# TC37XPD register map
Vendor: Infineon; Series: ATVMC; File version: 100
CPU: other r0p0, little endian, MPU, FPU, vendor SysTick, 4 interrupt priority bits
Registers are 32-bit, read-write, reset 0x0 unless marked. A register's access mark holds for its fields unless they carry their own. Offsets are from the block's base; [hi:lo] are bit positions; lines under a group give offsets from that group; {n}, {i} and the like mark numbered series; 'fields as' and 'values as' point back to an identical list.

## GTM (part 11 of 13)
Base 0xF0100000
{0xE8000+0x800*i} ATOM[{i}] (i=0..5) group
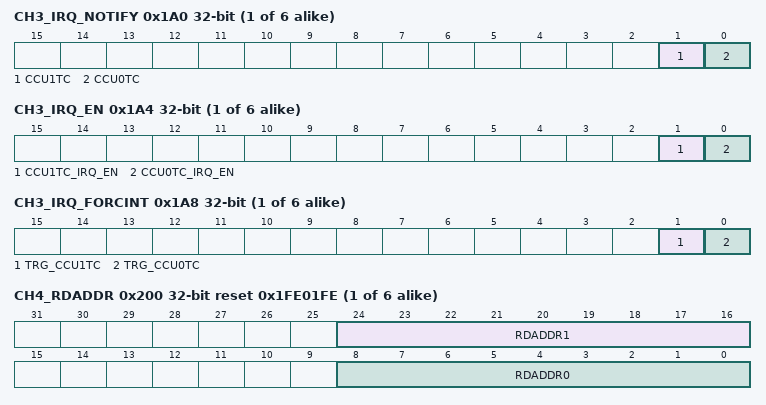
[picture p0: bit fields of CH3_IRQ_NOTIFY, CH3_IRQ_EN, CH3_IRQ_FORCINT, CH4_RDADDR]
  0x1A0 CH3_IRQ_NOTIFY — ATOM0 Channel 7 Interrupt Notification Register resetvalue={Application Reset:0x0}
    [1] CCU1TC — CCU1TC CCU1 Trigger condition interrupt for channel x. The notification of the interrupt is only triggered one time after reaching the condition CN0 gt CM1. To enable re trigger of the notification first the condition CN0 lt CM1 has to be reached. Note This bit will be cleared on a CPU write access of value 1. A read access leaves the bit unchanged. Note This description differs to the description in the Bosch spec. Note If bit SR0 TRIG is set to 1 only valid in SOMP mode this interrupt notify flag is set in case of SR0 is equal to CN0 and not set in case of CM1 gt lt CN0.
    [0] CCU0TC — CCU0 Trigger condition interrupt for channel x. The notification of the interrupt is only triggered one time after reaching the condition CN0 gt CM0. To enable re trigger of the notification first the condition CN0 lt CM1 has to be reached. Note This bit will be cleared on a CPU write access of value 1. A read access leaves the bit unchanged. Note This description differs to the description in the Bosch spec.
  0x1A4 CH3_IRQ_EN — ATOM0 Channel 7 Interrupt Enable Register resetvalue={Application Reset:0x0}
    [1] CCU1TC_IRQ_EN — ATOM CCU1TC IRQ interrupt enable. See bit 0.
    [0] CCU0TC_IRQ_EN — ATOM CCU0TC IRQ interrupt enable
  0x1A8 CH3_IRQ_FORCINT — ATOM0 Channel 7 Software Interrupt Generation Register resetvalue={Application Reset:0x0}
    [1] TRG_CCU1TC — Trigger ATOM CCU1TC IRQ interrupt by software. Note This bit is cleared automatically after write. Note This bit is write protected by bit RF PROT of register GTM CTRL
    [0] TRG_CCU0TC — Trigger ATOM CCU0TC IRQ interrupt by software. Note This bit is cleared automatically after write. Note This bit is write protected by bit RF PROT of register GTM CTRL
  0x1AC CH3_IRQ_MODE — ATOM0 Channel 7 Interrupt Mode Configuration Register resetvalue={Application Reset:0x0}
    [1:0] IRQ_MODE — IRQ mode selection. Note The interrupt modes are described in CROSSREFERENCE .
  0x200 CH4_RDADDR reset 0x1FE01FE — ATOM0 Channel 7 ARU read address Register resetvalue={Application Reset:0x1FE01FE}
    [24:16] RDADDR1 — ARU Read address 1. Note The ATOM channel switches to this read address when requested in the ARU control bits 52 to 48 with the pattern 111 . The channel switches back to the RDADDR0 after one ARU data package was received on RDADDR1 and the compare match event is occurred. Note This read address is only applicable in SOMC mode. Note This bit field is only writable if channel is disabled.
    [8:0] RDADDR0 — ARU Read address 0. Note This read address is used by the ATOM channel to receive data from ARU immediately after the channel and ARU access is enabled see ATOM i CH x CTRL register for details . Note This bit field is only writable if channel is disabled.
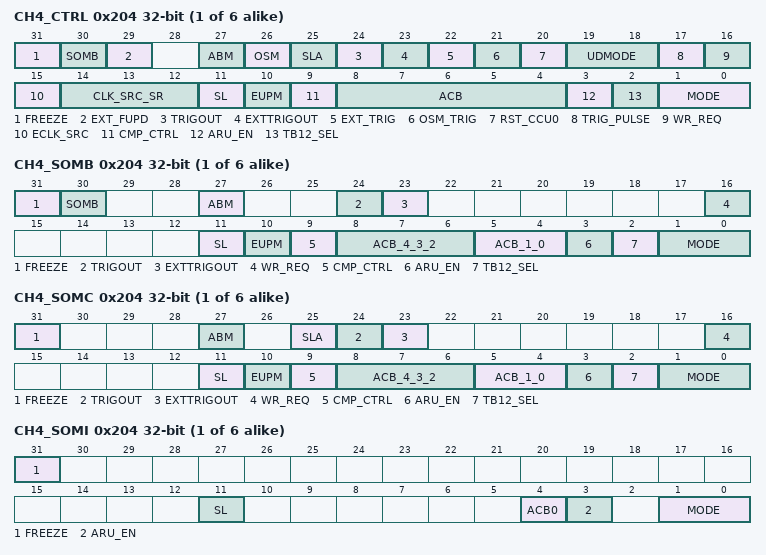
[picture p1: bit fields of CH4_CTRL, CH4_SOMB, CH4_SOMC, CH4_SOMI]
  0x204 CH4_CTRL (reset mask 0xFFFFF7FF) — ATOM0 Channel 7 Control Register resetvalue={Application Reset:0x0800,Application Reset:0x0,Application Reset:0x0,Application Reset:0x0,Application Reset:0x0,Application Reset:0x0}
    [31] FREEZE — FREEZE. Note if channel is disabled and ouptut is enabled in SOMP mode with UDMODE 0b00 the output is dependng directly on SL bit independent on FREEZE mode.
    [30] SOMB — SOMB mode
    [29] EXT_FUPD — External forced update. Note This bit is only applicable in SOMP and SOMS mode.
    [27] ABM — ARU blocking mode. Note This bit is only applicable in SOMC and SOMB mode.
    [26] OSM — One shot mode. Note This bit is only applicable in SOMP and SOMS modes.
    [25] SLA — Serve last ARU communication strategy. This bit is only applicable in SOMC mode. Please note that setting of this bit has only effect when ACBI 4 2 is configured for serve last compare strategy 100 101 or 110 . When this bit is not set the captured time stamps in the shadow registers SRx are only provided after the CCU1 match occurred. The ACBO 4 3 bits always return 10 in that case. By setting this bit the ATOM channel also provides the captured time stamps after the CCU0 match event to the ARU. The ACBO 4 3 bits are set to 01 in that case. After the CCU1 match event the time stamps are captured again in the SRx registers and provided to the ARU. The ACBO 4 3 bits are set to 10 . When the data in the shadow registers after the CCU0 match was not consumed by an ARU destination and the CCU1 match occurs the data in the shadow registers is overwritten by the new captured time stamps. The ATOM channel does not request new data from the ARU when the CCU0 match values are read from an ARU destination.
    [24] TRIGOUT — Trigger output selection output signal TRIG CHx of module ATOM CHx
    [23] EXTTRIGOUT — Select TIM EXT CAPTURE x as potential output signal TRIG x
    [22] EXT_TRIG — Select TIM EXT CAPTURE x as trigger signal
    [21] OSM_TRIG — Enable trigger of one shot pulse by trigger signal OSM TRIG. Note This bit should only be set if bit OSM 1 and bit RST CCU0 0.
    [20] RST_CCU0 — Reset source of CCU0. If RST CCU0 1 and UPEN CTRLx 1 are set TRIG x 1 or TIM EXT CAPTURE x triggers also the update of work register CM0 CM1 and CLK SRC . This bit is only applicable in SOMP mode. This bit should only be set if bit OSM 0 i.e. in continuous mode .
    [19:18] UDMODE — Up down counter mode. Note This mode is only applicable in SOMP mode.
    [17] TRIG_PULSE — Trigger output pulse length of one SYS CLK period
    [16] WR_REQ — CPU Write request bit for late compare register update. Note The CPU can disable subsequent ARU read requests by the channel and can update the shadow registers with new compare values while the compare units operate on old compare values received by former ARU accesses if occurred. Note On a compare match event the WR REQ bit will be reset by hardware. Note At the point of the force update only the shadow registers SR0 and SR1 are transferred into the CM0 CM1 registers. The output action is still defined by the ACBI bit field described by the ARU together with the old compare values for CM0 CM1. Note This bit is only applicable in SOMC and SOMB mode.
    [15] ECLK_SRC — Extend CLK SRC. Note This bit is only applicable in SOMP and SOMS mode. See bit CLK SRC SR description for details.
    [14:12] CLK_SRC_SR — Actual CMU clock source SOMS shadow register for CMU clock source SOMP . If ECLK SRC 0 ECLK SRC 1 This register is a shadow register for the register CLK SRC. Thus if the CMU CLK source for PWM generation should be changed during operation the old CMU CLK has to operate until the update of the ATOM channels internal CLK SRC register by the CLK SRC SR content is done either by an end of a period or a forced update. After channel reset the selected CLK SRC value is the SYS CLK input of Global Clock Divider . To use in SOMP mode one of the CMU CLKx it is recommended to perform a forced update of CLK SRC with the value of CLK SRC SR value before with enabling the channel. In case of ECLK SRC 1 and CLK SRC SR 011 100 101 110 a force update leads to an immediate update of CM0 CM1 and CLK SRC.
    [11] SL — Initial signal level. Reset value depends on the hardware configuration chosen by silicon vendor. If the output is disabled the output ATOM OUT x is set to inverse SL independent of the ATOM channel mode. If FREEZE 0 following notes are valid In SOMP SOMI SOMS mode if the channel is disabled the internal register SOUR inside ATOM sub unit SOU is set to inverse value of SL. By enabling the channel the register SOUR is not changed. Thus if the output is enabled afterwards the output ATOM OUT x is the inverse value of SL. In SOMC mode if the channel is disabled the internal register SOUR inside ATOM sub unit SOU is set to value of SL. By enabling the channel the register SOUR is not changed. Thus if the output is enabled and the channel is disabled the output ATOM OUT x is the value of SL. If FREEZE 1 the following notes are valid If the channel is disabled the output register of SOU unit is not changed and output ATOM OUT x is not changed.
    [10] EUPM — Extended update mode. If EUPM 1 a write access to CM0 or CM1 never causes an AEI write status 10 . This bit is only applicable in SOMC and SOMB mode.
    [9] CMP_CTRL — CCUx compare strategy select. Note This bit is only applicable in SOMC mode.
    [8:4] ACB — ATOM Mode control bits. These bits have different meaning in the different ATOM channel modes. Please refer to the mode description sections. SOMI CROSSREFERENCE and CROSSREFERENCE for register description. SOMC CROSSREFERENCE and CROSSREFERENCE for register description. SOMP CROSSREFERENCE and CROSSREFERENCE for register description. SOMS CROSSREFERENCE and CROSSREFERENCE for register description. SOMB CROSSREFERENCE and CROSSREFERENCE for register description.
    [3] ARU_EN — ARU input stream enable
    [2] TB12_SEL — Select time base value TBU TS1 or TBU TS2. Note This bit is only applicable in SOMC mode.
    [1:0] MODE — ATOM channel mode select
  0x204 CH4_SOMB (reset mask 0xFFFFF7FF) — ATOM0 Channel 7 Control Register in SOMB Mode resetvalue={Application Reset:0x0800,Application Reset:0x0,Application Reset:0x0,Application Reset:0x0,Application Reset:0x0,Application Reset:0x0}
    [31] FREEZE
    [30] SOMB — SOMB SOMB mode
    [27] ABM — ARU blocking mode
    [24] TRIGOUT — Trigger output selection output signal TRIG CHx of module ATOM CHx
    [23] EXTTRIGOUT — TIM EXT CAPTURE x as potential output signal TRIG x
    [16] WR_REQ — CPU Write request bit for late compare register update. The CPU can disable subsequent ARU read requests by the channel and can update the shadow registers with new compare values while the compare units operate on old compare values received by former ARU accesses if occurred. On a compare match event the WR REQ bit will be reset by hardware. At the point of the force update only the shadow registers SR0 and SR1 are transferred into the CM0 CM1 registers. The output action is still defined by the ACBI bit field described by the ARU together with the old compare values for CM0 CM1.
    [11] SL — Initial signal level after channel enable. Reset value depends on the hardware configuration chosen by silicon vendor. If the output is disabled the output ATOM OUT x is set to inverse value of SL. If FREEZE 0 the following note is valid If the channel is disabled the output register of SOU unit is set to value of SL. If FREEZE 1 the following note is valid If the channel is disabled the output register of SOU unit is not changed and output ATOM OUT x is not changed.
    [10] EUPM — Extended update mode. If EUPM 1 and after a CCU0 compare match if ARU EN 0 written CM0 value not stored. if ARU EN 1 ARU read request is continued and CM1 is updated until CCU1 compare match. Received CM0 is not stored. This bit is only applicable in SOMC and SOMB mode.
    [9] CMP_CTRL — CCUx compare strategy select. The compare unit CCU0 or CCU1 that compares against TBU TS0 depending on CCUx control mode defined by ACB CM 4 2 always performs a greater equal comparison independent of the CMP CTRL bit.
    [8:6] ACB_4_3_2 — ATOM SOMB compare strategy. These bits are only applicable if ARU EN 0.
    [5:4] ACB_1_0 — Signal level control bits. Note These bits are only applicable if ARU EN 0.
    [3] ARU_EN — ARU Input stream enable
    [2] TB12_SEL — Select time base value TBU TS1 or TBU TS2. This bit is only applicable if three time bases are present in the GTM. Otherwise this bit is reserved.
    [1:0] MODE — ATOM channel mode select. Not used in ATOM SOMB mode.
  0x204 CH4_SOMC (reset mask 0xFFFFF7FF) — ATOM0 Channel 7 Control Register in SOMC Mode resetvalue={Application Reset:0x0800,Application Reset:0x0,Application Reset:0x0,Application Reset:0x0,Application Reset:0x0,Application Reset:0x0}
    [31] FREEZE
    [27] ABM — ARU blocking mode
    [25] SLA — Serve last ARU communication strategy. Please note that setting of this bit has only effect when ACBI 4 2 is configured for serve last compare strategy quot 100 quot quot 101 quot or quot 110 quot . When this bit is not set the captured time stamps in the shadow registers SRx are only provided after the CCU1 match occurred. The ACBO 4 3 bits always return quot 10 quot in that case. By setting this bit the ATOM channel also provides the captured time stamps after the CCU0 match event to the ARU. The ACBO 4 3 bits are set to 8220 01 8221 in that case. After the CCU1 match event the time stamps are captured again in the SRx registers and provided to the ARU. The ACBO 4 3 bits are set to 8220 10 8221 . When the data in the shadow registers after the CCU0 match was not consumed by an ARU destination and the CCU1 match occurs the data in the shadow registers is overwritten by the new captured time stamps. The ATOM channel does not request new data from the ARU when the CCU0 match values are read from an ARU destination.
    [24] TRIGOUT — TRIGOUT Trigger output selection output signal TRIG CHx of module ATOM CHx
    [23] EXTTRIGOUT — Select TIM EXT CAPTURE x as potential output signal TRIG x
    [16] WR_REQ — CPU write request bit. The CPU can disable subsequent ARU read requests by the channel and can update the shadow registers with new compare values while the compare units operate on old compare values received by former ARU accesses if occurred. On a compare match event the WR REQ bit will be reset by hardware. At the point of the force update only the shadow registers SR0 and SR1 are transferred into the CM0 CM1 registers. The output action is still defined by the ACBI bit field described by the ARU together with the old compare values for CM0 CM1.
    [11] SL — Initial signal level after channel enable. Reset value depends on the hardware configuration chosen by silicon vendor. If the output is disabled the output ATOM OUT x is set to inverse value of SL. If FREEZE 0 following note is valid If the channel is disabled the output register of SOU unit is set to value of SL. If FREEZE 1 following note is valid If the channel is disabled the output register of SOU unit is not changed and output ATOM OUT x is not changed.
    [10] EUPM — Extended Update Mode. If EUPM 1 and after a CCU0 compare match If ARU EN 0 written CM0 value not stored. If ARU EN 1 ARU read request is continued and CM1 is updated until CCU1 compare match. Received CM0 values are not stored. This bit is only applicable in SOMC and SOMB mode.
    [9] CMP_CTRL — CCUx compare strategy select. The compare unit CCU0 or CCU1 that compares against TBU TS0 depending on CCUx control mode defined by ACBI 4 2 or ACB42 always performs a greater equal comparison independent on CMP CTRL bit.
    [8:6] ACB_4_3_2 — ATOM control bits ACB 4 ACB 3 ACB 2 . Independent of ARU EN a writing of 0b111 cancels any pending CCU0 or CCU1 compare. Note These bits are defining the compare strategy only if ARU EN 0.
    [5:4] ACB_1_0 — Signal level control bits. These bits are only applicable if ARU EN 0.
    [3] ARU_EN — ARU Input stream enable
    [2] TB12_SEL — Select time base value TBU TS1 or TBU TS2. This bit is only applicable if three time bases are present in the GTM. Otherwise this bit is reserved.
    [1:0] MODE — ATOM channel mode select
  0x204 CH4_SOMI (reset mask 0xFFFFF7FF) — ATOM0 Channel 7 Control Register in SOMI Mode resetvalue={Application Reset:0x0800,Application Reset:0x0,Application Reset:0x0,Application Reset:0x0,Application Reset:0x0,Application Reset:0x0}
    [31] FREEZE
    [11] SL — Initial signal level after channel is enabled. Note Reset value depends on the hardware configuration chosen by silicon vendor. Note If the output is disabled the output ATOM OUT x is set to inverse value of SL. If FREEZE 0 following note is valid If the channel is disabled the output register of SOU unit is set to inverse value of SL. If FREEZE 1 following note is valid If the channel is disabled the output register of SOU unit is not changed and output ATOM OUT x is not changed.
    [4] ACB0 — ACB bit 0 . Note Bosch name ACB 0 .
    [3] ARU_EN — ARU Input stream enable
    [1:0] MODE — ATOM channel mode select
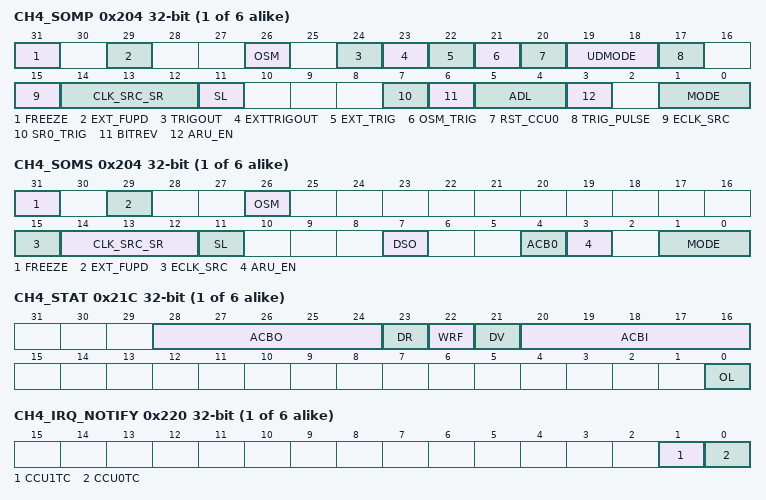
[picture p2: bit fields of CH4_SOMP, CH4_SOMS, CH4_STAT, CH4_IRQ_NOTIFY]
  0x204 CH4_SOMP (reset mask 0xFFFFF7FF) — ATOM0 Channel 7 Control Register in SOMP Mode resetvalue={Application Reset:0x0800,Application Reset:0x0,Application Reset:0x0,Application Reset:0x0,Application Reset:0x0,Application Reset:0x0}
    [31] FREEZE
    [29] EXT_FUPD — External forced update. This bit is only applicable in SOMP and SOMS mode.
    [26] OSM — One shot mode
    [24] TRIGOUT — Trigger output selection output signal TRIG CHx of module ATOM CHx
    [23] EXTTRIGOUT — Select TIM EXT CAPTURE x as potential output signal TRIG x
    [22] EXT_TRIG — Select TIM EXT CAPTURE x as trigger signal
    [21] OSM_TRIG — Enable trigger of one shot pulse by trigger signal OSM TRIG. This bit should only be set if bit OSM 1 and bit RST CCU0 0.
    [20] RST_CCU0 — Reset source of CCU0. If RST CCU0 1 and UPEN CTRLx 1 are set TRIG x 1 or TIM EXT CAPTURE x triggers also the update of work register CM0 CM1 and CLK SRC .
    [19:18] UDMODE — Up down counter mode. This mode is only applicable in SOMP mode.
    [17] TRIG_PULSE — Trigger output pulse length of one SYS CLK period
    [15] ECLK_SRC — Extend CLK SRC. See bit CLK SRC SR description for details.
    [14:12] CLK_SRC_SR — Shadow register for CMU clock source register CLK SRC. If ECLK SRC 0 ECLK SRC 1 This register is a shadow register for the register CLK SRC. Thus if the CMU CLK source for PWM generation should be changed during operation the old CMU CLK has to operate until the update of the ATOM channels internal CLK SRC register by the CLK SRC SR content is done either by an end of a period or a FORCE UPDATE. After channel reset the selected CLK SRC value is the SYS CLK input of Global Clock Divider . To use in SOMP mode one of the CMU CLKx it is recommended to perform a forced update of CLK SRC with the value of CLK SRC SR value before with enabling the channel.
    [11] SL — Signal level for pulse of PWM. Reset value depends on the hardware configuration chosen by silicon vendor. If the output is disabled the output ATOM OUT x is set to inverse value of SL FREEZE 0 the following note is valid If the channel is disabled the output register of SOU unit is set to inverse value of SL. If FREEZE 1 the following note is valid If the channel is disabled the output register of SOU unit is not changed and output ATOM OUT x is not changed.
    [7] SR0_TRIG — SR0 is used to generate a trigger on output ATOM i CH x OUT T if equal to CN0. This bit is only relevant in SOMP mode. This bit should only be set if RST CCU0 of this channel is 0.
    [6] BITREV — Bit reversing of output of counter register CN0. This bit enables the PCM mode. It is device specific in which channel the PCM mode is available. Please refer to device specific CROSSREFERENCE for this information.
    [5:4] ADL — ARU data select for SOMP. This bit field is only relevant in SOMP mode to select the ARU data source.
    [3] ARU_EN — ARU Input stream enable
    [1:0] MODE — ATOM channel mode select
  0x204 CH4_SOMS (reset mask 0xFFFFF7FF) — ATOM0 Channel 7 Control Register in SOMS Mode resetvalue={Application Reset:0x0800,Application Reset:0x0,Application Reset:0x0,Application Reset:0x0,Application Reset:0x0,Application Reset:0x0}
    [31] FREEZE
    [29] EXT_FUPD — External forced update. This bit is only applicable in SOMP and SOMS mode.
    [26] OSM — One shot mode
    [15] ECLK_SRC — Extend CLK SRC. See bit CLK SRC SR description for details.
    [14:12] CLK_SRC_SR — Shift frequency select for channel. If ECLK SRC 0 ECLK SRC 1 This register is a shadow register for the register CLK SRC. Thus if the CMU CLK source for PWM generation should be changed during operation the old CMU CLK has to operate until the update of the ATOM channels internal CLK SRC register by the CLK SRC SR content is done either by an end of a period or a FORCE UPDATE. After channel reset the selected CLK SRC value is the SYS CLK input of Global Clock Divider . To use in SOMP mode one of the CMU CLKx it is recommended to perform a forced update of CLK SRC with the value of CLK SRC SR value before with enabling the channel.
    [11] SL — Defines signal level when channel and output is disabling. Reset value depends on the hardware configuration chosen by silicon vendor. If the output is enabled the output ATOM OUT x is set to bit 0 or 23 of CM1 register. If the output is disabled the output ATOM OUT x is set to inverse value of SL. An enable or disable of the channel x has no effect on ATOM OUT x . The inverse value of SL is shifted into the CM1 register. If FREEZE 0 the following note is valid If the channel is disabled the output register of SOU unit is set to inverse value of SL. If FREEZE 1 the following note is valid If the channel is disabled the output register of SOU unit is not changed and output ATOM OUT x is not changed.
    [7] DSO — Double Shift Output. Note If DSO 1 only shift right is possible.
    [4] ACB0 — Shift direction for CM1 register. The data that has to be shifted out has to be aligned inside the CM1 register according to the defined shift direction. This bit is only applicable if ARU EN 0. If the direction ACB0 is changed the output ATOM OUT x switches immediately to the other first bit of CM1 bit 0 if ACB0 0 bit 23 if ACB0 160 160 1 .
    [3] ARU_EN — ARU Input stream enable
    [1:0] MODE — ATOM channel mode select
  0x208 CH4_SR0 — ATOM0 Channel 7 CCU0 Compare Shadow Register resetvalue={Application Reset:0x0}
    [23:0] SR0 — ATOM channel x shadow register SR0. Note The SR0 register is used as shadow register for CM0 in SOMP and SOMS modes and is used as capture register for time base TBU TS0 in SOMC mode.
  0x20C CH4_SR1 — ATOM0 Channel 7 CCU1 Compare Shadow Register resetvalue={Application Reset:0x0}
    [23:0] SR1 — ATOM channel x shadow register SR1. Note The SR1 register is used as shadow register for CM1 in SOMP and SOMS modes and is used as capture register for time base TBU TS1 or TBU TS2 when selected in ATOM i CH x CTRL register in SOMC mode.
  0x210 CH4_CM0 — ATOM0 Channel 7 CCU0 Compare Register resetvalue={Application Reset:0x0}
    [23:0] CM0 — ATOM CCU0 compare register
  0x214 CH4_CM1 — ATOM0 Channel 7 CCU1 Compare Register resetvalue={Application Reset:0x0}
    [23:0] CM1 — ATOM CCU1 compare register
  0x218 CH4_CN0 — ATOM0 Channel 7 CCU0 Counter Register resetvalue={Application Reset:0x0}
    [23:0] CN0 — ATOM CCU0 counter register
  0x21C CH4_STAT access per field — ATOM0 Channel 7 Status Register resetvalue={Application Reset:0x0}
    [28:24] ACBO ro — ATOM Internal status bits. ACBO 3 1 CCU0 Compare match occurred. ACBO 4 1 CCU1 Compare match occurred. Note These bits are only set in SOMC mode. Note ACBO is reset to 0b00000 on an update of register CM0 or CM1 via ARU or CPU . Note In SOMC mode these bits are sent as ARU control bits 52..48.
    [23] DR ro — ARU data rejected flag. Note The flag is cleared if valid data is received and stored via ARU.
    [22] WRF rw — Write request of CPU failed for late update. Note This bit is only applicable in SOMC and SOMB mode. Bit WRF can be reset by writing a 1 to it.
    [21] DV ro — Valid ARU Data stored in compare registers. Note This bit is only applicable in SOMC and SOMB mode. The CPU can determine the status of the ARU transfers with this bit. After the compare event occurred the bit is reset by hardware .
    [20:16] ACBI ro — ATOM Mode control bits. Note For ATOM SOMI SOMC SOMP and SOMS mode this register serves as a mirror for the five ARU control bits received through the ARU interface. The bits are valid when the DV bit is set. Note For SOMB mode this bit field serves as the work register of the compare strategy. It can be updated with the value of bit field ACB of register ATOM i CH x CTRL or the value of internal shadow register ACB SR.
    [0] OL ro — Actual output signal level of ATOM CHx OUT. Note Reset value is the inverted value of bit SL which depends on the hardware configuration chosen by silicon vendor.
  0x220 CH4_IRQ_NOTIFY — ATOM0 Channel 7 Interrupt Notification Register resetvalue={Application Reset:0x0}
    fields as ATOM[0].CH3_IRQ_NOTIFY
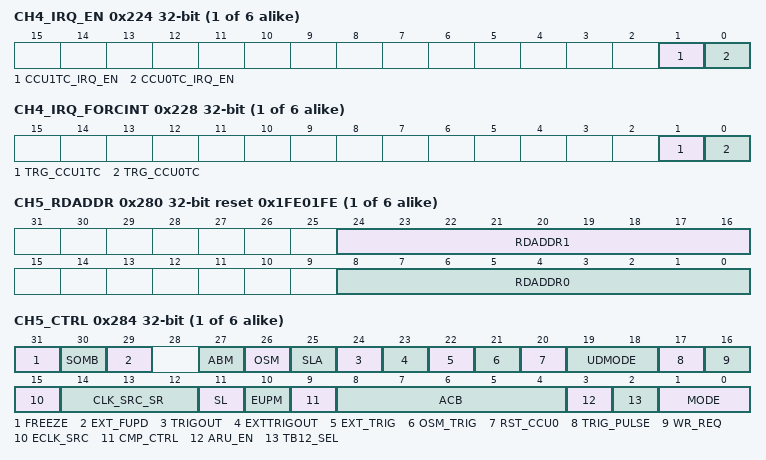
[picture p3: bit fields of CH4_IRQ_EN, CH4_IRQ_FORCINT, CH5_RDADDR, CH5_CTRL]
  0x224 CH4_IRQ_EN — ATOM0 Channel 7 Interrupt Enable Register resetvalue={Application Reset:0x0}
    fields as ATOM[0].CH3_IRQ_EN
  0x228 CH4_IRQ_FORCINT — ATOM0 Channel 7 Software Interrupt Generation Register resetvalue={Application Reset:0x0}
    fields as ATOM[0].CH3_IRQ_FORCINT
  0x22C CH4_IRQ_MODE — ATOM0 Channel 7 Interrupt Mode Configuration Register resetvalue={Application Reset:0x0}
    fields as ATOM[0].CH3_IRQ_MODE
  0x280 CH5_RDADDR reset 0x1FE01FE — ATOM0 Channel 7 ARU read address Register resetvalue={Application Reset:0x1FE01FE}
    fields as ATOM[0].CH4_RDADDR
  0x284 CH5_CTRL (reset mask 0xFFFFF7FF) — ATOM0 Channel 7 Control Register resetvalue={Application Reset:0x0800,Application Reset:0x0,Application Reset:0x0,Application Reset:0x0,Application Reset:0x0,Application Reset:0x0}
    fields as ATOM[0].CH4_CTRL
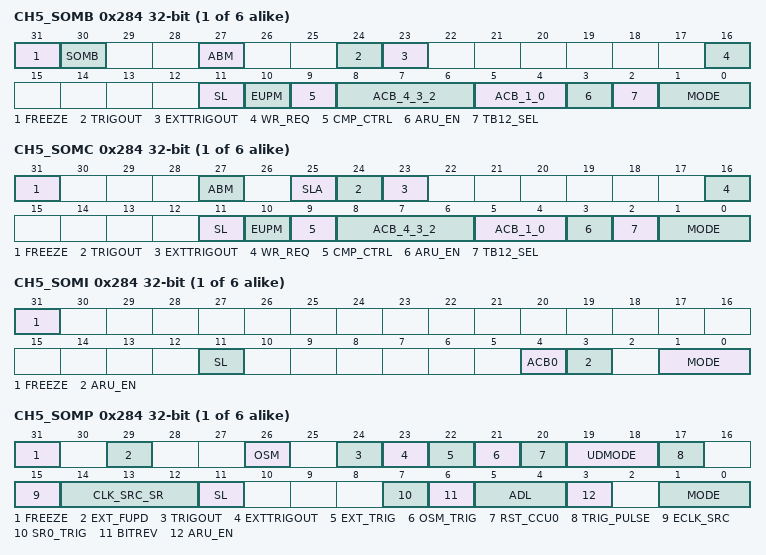
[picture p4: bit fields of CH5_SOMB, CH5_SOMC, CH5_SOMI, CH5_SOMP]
  0x284 CH5_SOMB (reset mask 0xFFFFF7FF) — ATOM0 Channel 7 Control Register in SOMB Mode resetvalue={Application Reset:0x0800,Application Reset:0x0,Application Reset:0x0,Application Reset:0x0,Application Reset:0x0,Application Reset:0x0}
    fields as ATOM[0].CH4_SOMB
  0x284 CH5_SOMC (reset mask 0xFFFFF7FF) — ATOM0 Channel 7 Control Register in SOMC Mode resetvalue={Application Reset:0x0800,Application Reset:0x0,Application Reset:0x0,Application Reset:0x0,Application Reset:0x0,Application Reset:0x0}
    fields as ATOM[0].CH4_SOMC
  0x284 CH5_SOMI (reset mask 0xFFFFF7FF) — ATOM0 Channel 7 Control Register in SOMI Mode resetvalue={Application Reset:0x0800,Application Reset:0x0,Application Reset:0x0,Application Reset:0x0,Application Reset:0x0,Application Reset:0x0}
    fields as ATOM[0].CH4_SOMI
  0x284 CH5_SOMP (reset mask 0xFFFFF7FF) — ATOM0 Channel 7 Control Register in SOMP Mode resetvalue={Application Reset:0x0800,Application Reset:0x0,Application Reset:0x0,Application Reset:0x0,Application Reset:0x0,Application Reset:0x0}
    fields as ATOM[0].CH4_SOMP
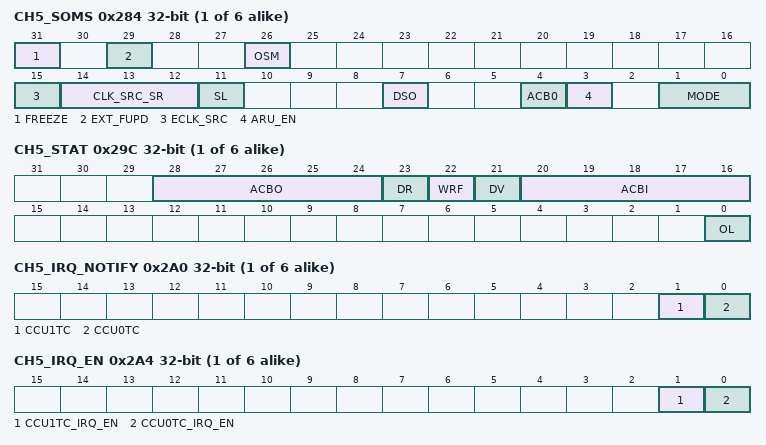
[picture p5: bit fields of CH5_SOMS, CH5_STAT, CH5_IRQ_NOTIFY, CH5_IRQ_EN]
  0x284 CH5_SOMS (reset mask 0xFFFFF7FF) — ATOM0 Channel 7 Control Register in SOMS Mode resetvalue={Application Reset:0x0800,Application Reset:0x0,Application Reset:0x0,Application Reset:0x0,Application Reset:0x0,Application Reset:0x0}
    fields as ATOM[0].CH4_SOMS
  0x288 CH5_SR0 — ATOM0 Channel 7 CCU0 Compare Shadow Register resetvalue={Application Reset:0x0}
    fields as ATOM[0].CH4_SR0
  0x28C CH5_SR1 — ATOM0 Channel 7 CCU1 Compare Shadow Register resetvalue={Application Reset:0x0}
    fields as ATOM[0].CH4_SR1
  0x290 CH5_CM0 — ATOM0 Channel 7 CCU0 Compare Register resetvalue={Application Reset:0x0}
    [23:0] CM0 — ATOM CCU0 compare register
  0x294 CH5_CM1 — ATOM0 Channel 7 CCU1 Compare Register resetvalue={Application Reset:0x0}
    [23:0] CM1 — ATOM CCU1 compare register
  0x298 CH5_CN0 — ATOM0 Channel 7 CCU0 Counter Register resetvalue={Application Reset:0x0}
    [23:0] CN0 — ATOM CCU0 counter register
  0x29C CH5_STAT access per field — ATOM0 Channel 7 Status Register resetvalue={Application Reset:0x0}
    fields as ATOM[0].CH4_STAT
  0x2A0 CH5_IRQ_NOTIFY — ATOM0 Channel 7 Interrupt Notification Register resetvalue={Application Reset:0x0}
    fields as ATOM[0].CH3_IRQ_NOTIFY
  0x2A4 CH5_IRQ_EN — ATOM0 Channel 7 Interrupt Enable Register resetvalue={Application Reset:0x0}
    fields as ATOM[0].CH3_IRQ_EN
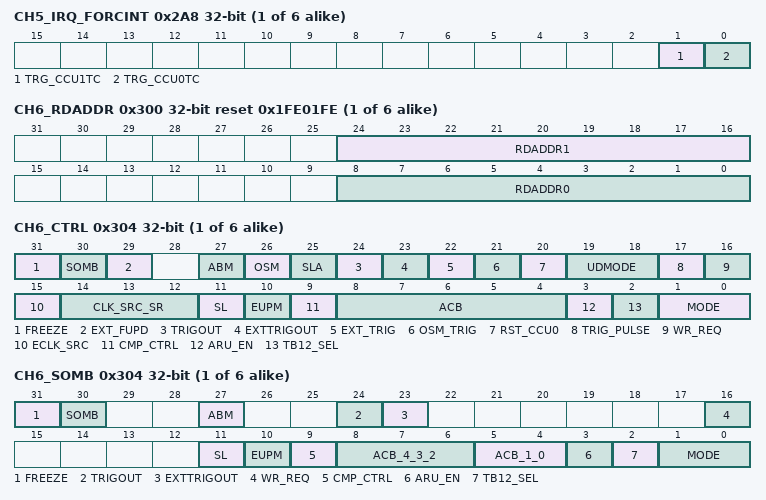
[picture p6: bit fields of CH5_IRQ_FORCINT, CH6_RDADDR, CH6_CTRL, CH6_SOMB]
  0x2A8 CH5_IRQ_FORCINT — ATOM0 Channel 7 Software Interrupt Generation Register resetvalue={Application Reset:0x0}
    fields as ATOM[0].CH3_IRQ_FORCINT
  0x2AC CH5_IRQ_MODE — ATOM0 Channel 7 Interrupt Mode Configuration Register resetvalue={Application Reset:0x0}
    fields as ATOM[0].CH3_IRQ_MODE
  0x300 CH6_RDADDR reset 0x1FE01FE — ATOM0 Channel 7 ARU read address Register resetvalue={Application Reset:0x1FE01FE}
    fields as ATOM[0].CH4_RDADDR
  0x304 CH6_CTRL (reset mask 0xFFFFF7FF) — ATOM0 Channel 7 Control Register resetvalue={Application Reset:0x0800,Application Reset:0x0,Application Reset:0x0,Application Reset:0x0,Application Reset:0x0,Application Reset:0x0}
    fields as ATOM[0].CH4_CTRL
  0x304 CH6_SOMB (reset mask 0xFFFFF7FF) — ATOM0 Channel 7 Control Register in SOMB Mode resetvalue={Application Reset:0x0800,Application Reset:0x0,Application Reset:0x0,Application Reset:0x0,Application Reset:0x0,Application Reset:0x0}
    fields as ATOM[0].CH4_SOMB
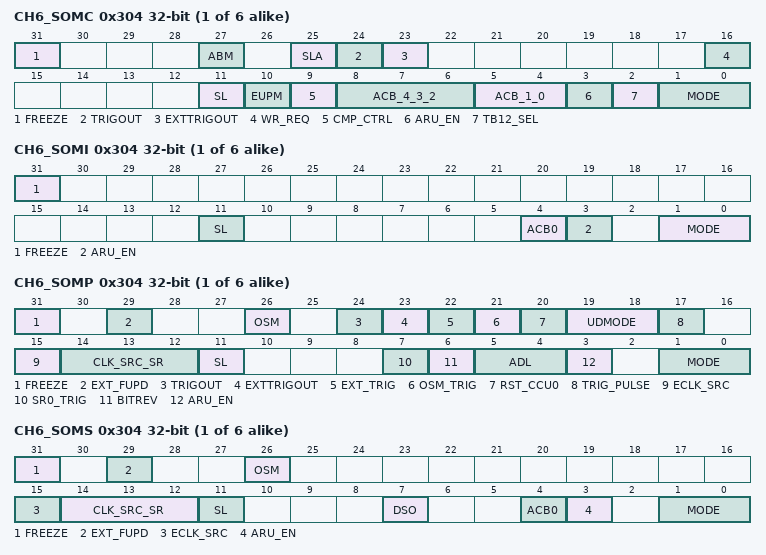
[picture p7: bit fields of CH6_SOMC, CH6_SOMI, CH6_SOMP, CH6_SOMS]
  0x304 CH6_SOMC (reset mask 0xFFFFF7FF) — ATOM0 Channel 7 Control Register in SOMC Mode resetvalue={Application Reset:0x0800,Application Reset:0x0,Application Reset:0x0,Application Reset:0x0,Application Reset:0x0,Application Reset:0x0}
    fields as ATOM[0].CH4_SOMC
  0x304 CH6_SOMI (reset mask 0xFFFFF7FF) — ATOM0 Channel 7 Control Register in SOMI Mode resetvalue={Application Reset:0x0800,Application Reset:0x0,Application Reset:0x0,Application Reset:0x0,Application Reset:0x0,Application Reset:0x0}
    fields as ATOM[0].CH4_SOMI
  0x304 CH6_SOMP (reset mask 0xFFFFF7FF) — ATOM0 Channel 7 Control Register in SOMP Mode resetvalue={Application Reset:0x0800,Application Reset:0x0,Application Reset:0x0,Application Reset:0x0,Application Reset:0x0,Application Reset:0x0}
    fields as ATOM[0].CH4_SOMP
  0x304 CH6_SOMS (reset mask 0xFFFFF7FF) — ATOM0 Channel 7 Control Register in SOMS Mode resetvalue={Application Reset:0x0800,Application Reset:0x0,Application Reset:0x0,Application Reset:0x0,Application Reset:0x0,Application Reset:0x0}
    fields as ATOM[0].CH4_SOMS
  0x308 CH6_SR0 — ATOM0 Channel 7 CCU0 Compare Shadow Register resetvalue={Application Reset:0x0}
    fields as ATOM[0].CH4_SR0
  0x30C CH6_SR1 — ATOM0 Channel 7 CCU1 Compare Shadow Register resetvalue={Application Reset:0x0}
    fields as ATOM[0].CH4_SR1
  0x310 CH6_CM0 — ATOM0 Channel 7 CCU0 Compare Register resetvalue={Application Reset:0x0}
    [23:0] CM0 — ATOM CCU0 compare register
  0x314 CH6_CM1 — ATOM0 Channel 7 CCU1 Compare Register resetvalue={Application Reset:0x0}
    [23:0] CM1 — ATOM CCU1 compare register
  0x318 CH6_CN0 — ATOM0 Channel 7 CCU0 Counter Register resetvalue={Application Reset:0x0}
    [23:0] CN0 — ATOM CCU0 counter register
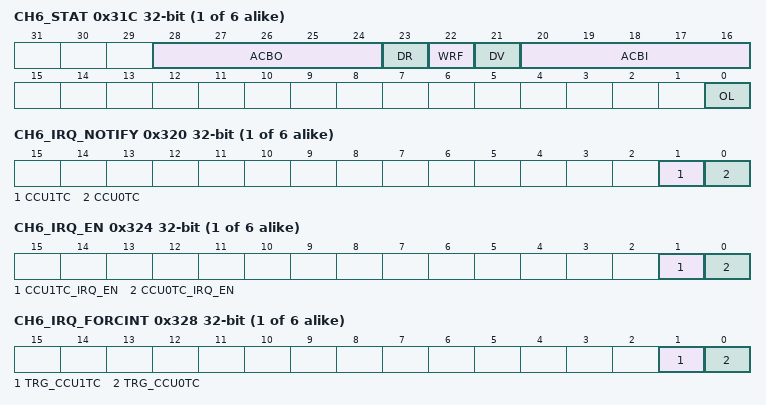
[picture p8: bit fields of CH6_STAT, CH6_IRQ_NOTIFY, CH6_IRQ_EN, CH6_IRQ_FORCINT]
  0x31C CH6_STAT access per field — ATOM0 Channel 7 Status Register resetvalue={Application Reset:0x0}
    fields as ATOM[0].CH4_STAT
  0x320 CH6_IRQ_NOTIFY — ATOM0 Channel 7 Interrupt Notification Register resetvalue={Application Reset:0x0}
    fields as ATOM[0].CH3_IRQ_NOTIFY
  0x324 CH6_IRQ_EN — ATOM0 Channel 7 Interrupt Enable Register resetvalue={Application Reset:0x0}
    fields as ATOM[0].CH3_IRQ_EN
  0x328 CH6_IRQ_FORCINT — ATOM0 Channel 7 Software Interrupt Generation Register resetvalue={Application Reset:0x0}
    fields as ATOM[0].CH3_IRQ_FORCINT
  0x32C CH6_IRQ_MODE — ATOM0 Channel 7 Interrupt Mode Configuration Register resetvalue={Application Reset:0x0}
    fields as ATOM[0].CH3_IRQ_MODE
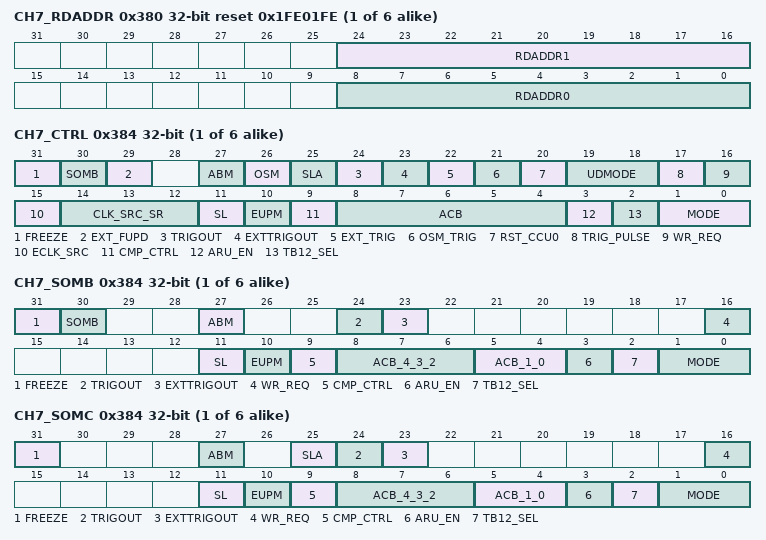
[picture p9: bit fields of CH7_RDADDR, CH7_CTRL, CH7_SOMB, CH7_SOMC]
  0x380 CH7_RDADDR reset 0x1FE01FE — ATOM0 Channel 7 ARU read address Register resetvalue={Application Reset:0x1FE01FE}
    fields as ATOM[0].CH4_RDADDR
  0x384 CH7_CTRL (reset mask 0xFFFFF7FF) — ATOM0 Channel 7 Control Register resetvalue={Application Reset:0x0800,Application Reset:0x0,Application Reset:0x0,Application Reset:0x0,Application Reset:0x0,Application Reset:0x0}
    fields as ATOM[0].CH4_CTRL
  0x384 CH7_SOMB (reset mask 0xFFFFF7FF) — ATOM0 Channel 7 Control Register in SOMB Mode resetvalue={Application Reset:0x0800,Application Reset:0x0,Application Reset:0x0,Application Reset:0x0,Application Reset:0x0,Application Reset:0x0}
    fields as ATOM[0].CH4_SOMB
  0x384 CH7_SOMC (reset mask 0xFFFFF7FF) — ATOM0 Channel 7 Control Register in SOMC Mode resetvalue={Application Reset:0x0800,Application Reset:0x0,Application Reset:0x0,Application Reset:0x0,Application Reset:0x0,Application Reset:0x0}
    fields as ATOM[0].CH4_SOMC
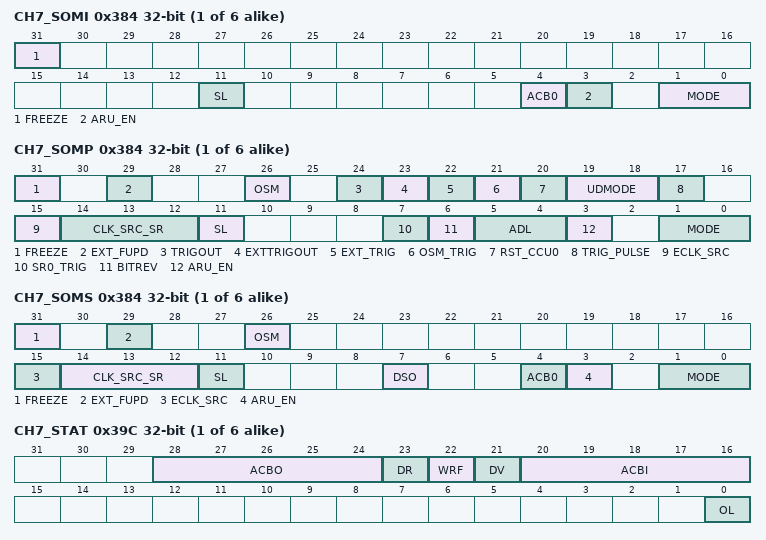
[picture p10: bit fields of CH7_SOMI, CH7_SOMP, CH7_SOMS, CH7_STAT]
  0x384 CH7_SOMI (reset mask 0xFFFFF7FF) — ATOM0 Channel 7 Control Register in SOMI Mode resetvalue={Application Reset:0x0800,Application Reset:0x0,Application Reset:0x0,Application Reset:0x0,Application Reset:0x0,Application Reset:0x0}
    fields as ATOM[0].CH4_SOMI
  0x384 CH7_SOMP (reset mask 0xFFFFF7FF) — ATOM0 Channel 7 Control Register in SOMP Mode resetvalue={Application Reset:0x0800,Application Reset:0x0,Application Reset:0x0,Application Reset:0x0,Application Reset:0x0,Application Reset:0x0}
    fields as ATOM[0].CH4_SOMP
  0x384 CH7_SOMS (reset mask 0xFFFFF7FF) — ATOM0 Channel 7 Control Register in SOMS Mode resetvalue={Application Reset:0x0800,Application Reset:0x0,Application Reset:0x0,Application Reset:0x0,Application Reset:0x0,Application Reset:0x0}
    fields as ATOM[0].CH4_SOMS
  0x388 CH7_SR0 — ATOM0 Channel 7 CCU0 Compare Shadow Register resetvalue={Application Reset:0x0}
    fields as ATOM[0].CH4_SR0
  0x38C CH7_SR1 — ATOM0 Channel 7 CCU1 Compare Shadow Register resetvalue={Application Reset:0x0}
    fields as ATOM[0].CH4_SR1
  0x390 CH7_CM0 — ATOM0 Channel 7 CCU0 Compare Register resetvalue={Application Reset:0x0}
    [23:0] CM0 — ATOM CCU0 compare register
  0x394 CH7_CM1 — ATOM0 Channel 7 CCU1 Compare Register resetvalue={Application Reset:0x0}
    [23:0] CM1 — ATOM CCU1 compare register
  0x398 CH7_CN0 — ATOM0 Channel 7 CCU0 Counter Register resetvalue={Application Reset:0x0}
    [23:0] CN0 — ATOM CCU0 counter register
  0x39C CH7_STAT access per field — ATOM0 Channel 7 Status Register resetvalue={Application Reset:0x0}
    fields as ATOM[0].CH4_STAT
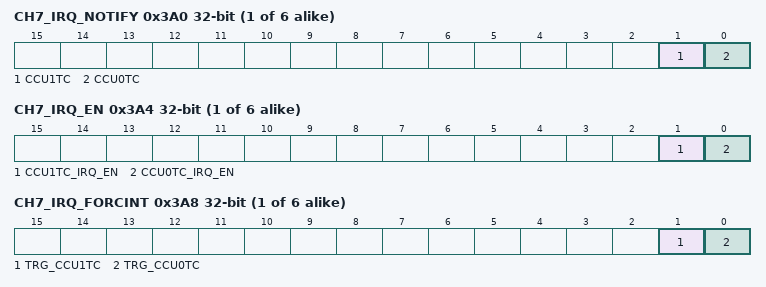
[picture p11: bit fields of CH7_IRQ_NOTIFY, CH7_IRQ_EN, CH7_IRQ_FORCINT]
  0x3A0 CH7_IRQ_NOTIFY — ATOM0 Channel 7 Interrupt Notification Register resetvalue={Application Reset:0x0}
    fields as ATOM[0].CH3_IRQ_NOTIFY
  0x3A4 CH7_IRQ_EN — ATOM0 Channel 7 Interrupt Enable Register resetvalue={Application Reset:0x0}
    fields as ATOM[0].CH3_IRQ_EN
  0x3A8 CH7_IRQ_FORCINT — ATOM0 Channel 7 Software Interrupt Generation Register resetvalue={Application Reset:0x0}
    fields as ATOM[0].CH3_IRQ_FORCINT
  0x3AC CH7_IRQ_MODE — ATOM0 Channel 7 Interrupt Mode Configuration Register resetvalue={Application Reset:0x0}
    fields as ATOM[0].CH3_IRQ_MODE
